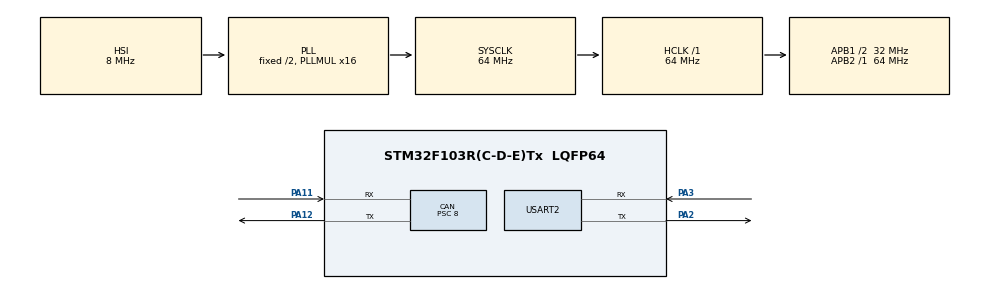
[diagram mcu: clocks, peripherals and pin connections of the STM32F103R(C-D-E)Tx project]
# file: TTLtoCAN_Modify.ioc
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Mcu.Family=STM32F1
FREERTOS.Queues01=Queue_CANtoUART,48,uint8_t,0,Dynamic,NULL,NULL;Queue_UARTtoCAN,100,uint8_t,0,Dynamic,NULL,NULL
NVIC.CAN1_RX1_IRQn=true\:5\:0\:false\:false\:true\:true\:true\:true
FREERTOS.Tasks01=Task_CANtoUART,0,128,StartTask_CANtoUART,Default,NULL,Dynamic,NULL,NULL;Task_UARTtoCAN,0,128,StartTask_UARTtoCAN,Default,NULL,Dynamic,NULL,NULL
PD1-OSC_OUT.Mode=HSE-External-Oscillator
CAN.CalculateBaudRate=250000
VP_SYS_VS_tim7.Mode=TIM7
USART2.Parity=PARITY_NONE
PA11.Mode=CAN_Activate
PD0-OSC_IN.Signal=RCC_OSC_IN
RCC.APB1CLKDivider=RCC_HCLK_DIV2
NVIC.USART2_IRQn=true\:5\:0\:false\:false\:true\:true\:true\:true
CAN.CalculateTimeBit=4000.00
RCC.SYSCLKSource=RCC_SYSCLKSOURCE_PLLCLK
ProjectManager.StackSize=0x400
PD1-OSC_OUT.Signal=RCC_OSC_OUT
PA13.Signal=SYS_JTMS-SWDIO
PA3.Mode=Asynchronous
CAN.BS2=CAN_BS2_2TQ
PA12.Signal=CAN_TX
CAN.Prescaler=8
CAN.BS1=CAN_BS1_13TQ
ProjectManager.TargetToolchain=Makefile
RCC.HCLKFreq_Value=64000000
RCC.APB2TimFreq_Value=64000000
RCC.USBFreq_Value=64000000
NVIC.CAN1_SCE_IRQn=true\:5\:0\:false\:false\:true\:true\:true\:true
RCC.AHBFreq_Value=64000000
PD0-OSC_IN.Mode=HSE-External-Oscillator
RCC.HSE_VALUE=16000000
board=custom
RCC.PLLMUL=RCC_PLL_MUL16
RCC.APB2Freq_Value=64000000
PA14.Mode=Serial_Wire
NVIC.USB_LP_CAN1_RX0_IRQn=true\:5\:0\:false\:false\:true\:true\:true\:true
CAN.NART=ENABLE
VP_FREERTOS_VS_CMSIS_V1.Mode=CMSIS_V1
PA13.Mode=Serial_Wire
Mcu.Name=STM32F103R(C-D-E)Tx
CAN.CalculateTimeQuantum=250.0
PA2.Signal=USART2_TX
RCC.SYSCLKFreq_VALUE=64000000
Mcu.Package=LQFP64
NVIC.TimeBase=TIM7_IRQn
PA12.Mode=CAN_Activate
USART2.VirtualMode=VM_ASYNC
PA11.Signal=CAN_RX
NVIC.TimeBaseIP=TIM7
PA14.Signal=SYS_JTCK-SWCLK
ProjectManager.HeapSize=0x200
USART2.WordLength=WORDLENGTH_8B
NVIC.PriorityGroup=NVIC_PRIORITYGROUP_4
RCC.APB1TimFreq_Value=64000000
PA2.Mode=Asynchronous
RCC.APB1Freq_Value=32000000
NVIC.TIM7_IRQn=true\:0\:0\:false\:false\:true\:false\:false\:true
PA3.Signal=USART2_RX

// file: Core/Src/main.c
/* USER CODE BEGIN Header */
/**
  ******************************************************************************
  * @file           : main.c
  * @brief          : Main program body
  ******************************************************************************
  * @attention
  *
  * <h2><center>&copy; Copyright (c) 2021 STMicroelectronics.
  * All rights reserved.</center></h2>
  *
  * This software component is licensed by ST under Ultimate Liberty license
  * SLA0044, the "License"; You may not use this file except in compliance with
  * the License. You may obtain a copy of the License at:
  *                             www.st.com/SLA0044
  *
  ******************************************************************************
  */
/* USER CODE END Header */
#include "main.h"
#include "cmsis_os.h"
#include "can.h"
#include "usart.h"
#include "gpio.h"

/* USER CODE BEGIN PV */
CAN_TxHeaderTypeDef CAN_TxHeader;
CAN_RxHeaderTypeDef CAN_RxHeader1, CAN_RxHeader2;
/* USER CODE END PV */

void SystemClock_Config(void);
void MX_FREERTOS_Init(void);

int main(void)
{

  /* MCU Configuration--------------------------------------------------------*/

  /* Reset of all peripherals, Initializes the Flash interface and the Systick. */
  HAL_Init();

  /* Configure the system clock */
  SystemClock_Config();

  /* Initialize all configured peripherals */
  MX_GPIO_Init();
  MX_CAN_Init();
  MX_USART2_UART_Init();
  /* USER CODE BEGIN 2 */
  HAL_CAN_Start(&hcan);
  /* USER CODE END 2 */

  /* Call init function for freertos objects (in freertos.c) */
  MX_FREERTOS_Init();
  /* Start scheduler */
  osKernelStart();

  /* We should never get here as control is now taken by the scheduler */
  /* Infinite loop */
  while (1)
  {

  }
}

void SystemClock_Config(void)
{
  RCC_OscInitTypeDef RCC_OscInitStruct = {0};
  RCC_ClkInitTypeDef RCC_ClkInitStruct = {0};

  /** Initializes the RCC Oscillators according to the specified parameters
  * in the RCC_OscInitTypeDef structure.
  */
  RCC_OscInitStruct.OscillatorType = RCC_OSCILLATORTYPE_HSI;
  RCC_OscInitStruct.HSIState = RCC_HSI_ON;
  RCC_OscInitStruct.HSICalibrationValue = RCC_HSICALIBRATION_DEFAULT;
  RCC_OscInitStruct.PLL.PLLState = RCC_PLL_ON;
  RCC_OscInitStruct.PLL.PLLSource = RCC_PLLSOURCE_HSI_DIV2;
  RCC_OscInitStruct.PLL.PLLMUL = RCC_PLL_MUL16;
  if (HAL_RCC_OscConfig(&RCC_OscInitStruct) != HAL_OK)
  {
    Error_Handler();
  }
  /** Initializes the CPU, AHB and APB buses clocks
  */
  RCC_ClkInitStruct.ClockType = RCC_CLOCKTYPE_HCLK|RCC_CLOCKTYPE_SYSCLK
                              |RCC_CLOCKTYPE_PCLK1|RCC_CLOCKTYPE_PCLK2;
  RCC_ClkInitStruct.SYSCLKSource = RCC_SYSCLKSOURCE_PLLCLK;
  RCC_ClkInitStruct.AHBCLKDivider = RCC_SYSCLK_DIV1;
  RCC_ClkInitStruct.APB1CLKDivider = RCC_HCLK_DIV2;
  RCC_ClkInitStruct.APB2CLKDivider = RCC_HCLK_DIV1;

  if (HAL_RCC_ClockConfig(&RCC_ClkInitStruct, FLASH_LATENCY_2) != HAL_OK)
  {
    Error_Handler();
  }
}

 /**
  * @brief  Period elapsed callback in non blocking mode
  * @note   This function is called  when TIM7 interrupt took place, inside
  * HAL_TIM_IRQHandler(). It makes a direct call to HAL_IncTick() to increment
  * a global variable "uwTick" used as application time base.
  * @param  htim : TIM handle
  * @retval None
  */
void HAL_TIM_PeriodElapsedCallback(TIM_HandleTypeDef *htim)
{
  if (htim->Instance == TIM7) {
    HAL_IncTick();
  }
}

void Error_Handler(void)
{
  __disable_irq();
  while (1)
  {
  }
}

/************************ (C) COPYRIGHT STMicroelectronics *****END OF FILE****/

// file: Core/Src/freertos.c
/* USER CODE BEGIN Header */
/**
  ******************************************************************************
  * File Name          : freertos.c
  * Description        : Code for freertos applications
  ******************************************************************************
  * @attention
  *
  * <h2><center>&copy; Copyright (c) 2021 STMicroelectronics.
  * All rights reserved.</center></h2>
  *
  * This software component is licensed by ST under Ultimate Liberty license
  * SLA0044, the "License"; You may not use this file except in compliance with
  * the License. You may obtain a copy of the License at:
  *                             www.st.com/SLA0044
  *
  ******************************************************************************
  */
/* USER CODE END Header */

#include "FreeRTOS.h"
#include "task.h"
#include "main.h"
#include "cmsis_os.h"

osThreadId Task_CANtoUARTHandle;
osThreadId Task_UARTtoCANHandle;
osMessageQId Queue_CANtoUARTHandle;
osMessageQId Queue_UARTtoCANHandle;

void StartTask_CANtoUART(void const * argument);
void StartTask_UARTtoCAN(void const * argument);

void MX_FREERTOS_Init(void); /* (MISRA C 2004 rule 8.1) */

/* GetIdleTaskMemory prototype (linked to static allocation support) */
void vApplicationGetIdleTaskMemory( StaticTask_t **ppxIdleTaskTCBBuffer, StackType_t **ppxIdleTaskStackBuffer, uint32_t *pulIdleTaskStackSize );

/* USER CODE BEGIN GET_IDLE_TASK_MEMORY */
static StaticTask_t xIdleTaskTCBBuffer;
static StackType_t xIdleStack[configMINIMAL_STACK_SIZE];

void vApplicationGetIdleTaskMemory( StaticTask_t **ppxIdleTaskTCBBuffer, StackType_t **ppxIdleTaskStackBuffer, uint32_t *pulIdleTaskStackSize )
{
  *ppxIdleTaskTCBBuffer = &xIdleTaskTCBBuffer;
  *ppxIdleTaskStackBuffer = &xIdleStack[0];
  *pulIdleTaskStackSize = configMINIMAL_STACK_SIZE;
  /* place for user code */
}
/* USER CODE END GET_IDLE_TASK_MEMORY */

void MX_FREERTOS_Init(void) {

  /* Create the queue(s) */
  /* definition and creation of Queue_CANtoUART */
  osMessageQDef(Queue_CANtoUART, 48, uint8_t);
  Queue_CANtoUARTHandle = osMessageCreate(osMessageQ(Queue_CANtoUART), NULL);

  /* definition and creation of Queue_UARTtoCAN */
  osMessageQDef(Queue_UARTtoCAN, 100, uint8_t);
  Queue_UARTtoCANHandle = osMessageCreate(osMessageQ(Queue_UARTtoCAN), NULL);

  /* Create the thread(s) */
  /* definition and creation of Task_CANtoUART */
  osThreadDef(Task_CANtoUART, StartTask_CANtoUART, osPriorityNormal, 0, 128);
  Task_CANtoUARTHandle = osThreadCreate(osThread(Task_CANtoUART), NULL);

  /* definition and creation of Task_UARTtoCAN */
  osThreadDef(Task_UARTtoCAN, StartTask_UARTtoCAN, osPriorityNormal, 0, 128);
  Task_UARTtoCANHandle = osThreadCreate(osThread(Task_UARTtoCAN), NULL);

}

void StartTask_CANtoUART(void const * argument)
{
  /* USER CODE BEGIN StartTask_CANtoUART */
  osEvent event_CANtoUART;
  uint8_t *p = NULL;
  /* Infinite loop */
  for(;;)
  {
    osDelay(1);
    event_CANtoUART = osMessageGet(Queue_CANtoUARTHandle, osWaitForever);
    if(event_CANtoUART.status == osEventMessage)
    {
      p = (uint8_t *)event_CANtoUART.value.p;
    }
  }
  /* USER CODE END StartTask_CANtoUART */
}

void StartTask_UARTtoCAN(void const * argument)
{
  /* USER CODE BEGIN StartTask_UARTtoCAN */
  osEvent event_UARTtoCAN;
  /* Infinite loop */
  for(;;)
  {
    osDelay(1);
    event_UARTtoCAN = osMessageGet(Queue_UARTtoCANHandle, osWaitForever);
    if(event_UARTtoCAN.status == osEventMessage)
    {

    }
  }
  /* USER CODE END StartTask_UARTtoCAN */
}

/************************ (C) COPYRIGHT STMicroelectronics *****END OF FILE****/
